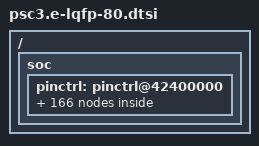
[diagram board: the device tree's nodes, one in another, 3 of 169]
/*
 * copyright (c) (2016-2025), Cypress Semiconductor Corporation
 * (an Infineon company) or an affiliate of Cypress Semiconductor Corporation.
 *
 * SPDX-License-Identifier: Apache-2.0
 *
 */

#include <zephyr/dt-bindings/gpio/gpio.h>
#include <zephyr/dt-bindings/pinctrl/ifx_cat1-pinctrl.h>
#include "psc3.dtsi"

/ {
	soc {

		pinctrl: pinctrl@42400000 {
			/* scb_i2c_scl */
			/omit-if-no-ref/ p1_3_scb1_i2c_scl: p1_3_scb1_i2c_scl {
				pinmux = <DT_CAT1_PINMUX(1, 3, HSIOM_SEL_ACT_7)>;
			};
			/omit-if-no-ref/ p2_1_scb1_i2c_scl: p2_1_scb1_i2c_scl {
				pinmux = <DT_CAT1_PINMUX(2, 1, HSIOM_SEL_ACT_7)>;
			};
			/omit-if-no-ref/ p3_2_scb4_i2c_scl: p3_2_scb4_i2c_scl {
				pinmux = <DT_CAT1_PINMUX(3, 2, HSIOM_SEL_ACT_7)>;
			};
			/omit-if-no-ref/ p4_2_scb4_i2c_scl: p4_2_scb4_i2c_scl {
				pinmux = <DT_CAT1_PINMUX(4, 2, HSIOM_SEL_ACT_7)>;
			};
			/omit-if-no-ref/ p5_1_scb3_i2c_scl: p5_1_scb3_i2c_scl {
				pinmux = <DT_CAT1_PINMUX(5, 1, HSIOM_SEL_ACT_7)>;
			};
			/omit-if-no-ref/ p6_1_scb3_i2c_scl: p6_1_scb3_i2c_scl {
				pinmux = <DT_CAT1_PINMUX(6, 1, HSIOM_SEL_ACT_7)>;
			};
			/omit-if-no-ref/ p7_0_scb2_i2c_scl: p7_0_scb2_i2c_scl {
				pinmux = <DT_CAT1_PINMUX(7, 0, HSIOM_SEL_ACT_7)>;
			};
			/omit-if-no-ref/ p8_1_scb5_i2c_scl: p8_1_scb5_i2c_scl {
				pinmux = <DT_CAT1_PINMUX(8, 1, HSIOM_SEL_ACT_7)>;
			};
			/omit-if-no-ref/ p9_0_scb0_i2c_scl: p9_0_scb0_i2c_scl {
				pinmux = <DT_CAT1_PINMUX(9, 0, HSIOM_SEL_DS_3)>;
			};

			/* scb_i2c_sda */
			/omit-if-no-ref/ p1_2_scb1_i2c_sda: p1_2_scb1_i2c_sda {
				pinmux = <DT_CAT1_PINMUX(1, 2, HSIOM_SEL_ACT_7)>;
			};
			/omit-if-no-ref/ p2_2_scb1_i2c_sda: p2_2_scb1_i2c_sda {
				pinmux = <DT_CAT1_PINMUX(2, 2, HSIOM_SEL_ACT_7)>;
			};
			/omit-if-no-ref/ p3_1_scb4_i2c_sda: p3_1_scb4_i2c_sda {
				pinmux = <DT_CAT1_PINMUX(3, 1, HSIOM_SEL_ACT_7)>;
			};
			/omit-if-no-ref/ p4_1_scb4_i2c_sda: p4_1_scb4_i2c_sda {
				pinmux = <DT_CAT1_PINMUX(4, 1, HSIOM_SEL_ACT_7)>;
			};
			/omit-if-no-ref/ p5_0_scb3_i2c_sda: p5_0_scb3_i2c_sda {
				pinmux = <DT_CAT1_PINMUX(5, 0, HSIOM_SEL_ACT_7)>;
			};
			/omit-if-no-ref/ p6_0_scb3_i2c_sda: p6_0_scb3_i2c_sda {
				pinmux = <DT_CAT1_PINMUX(6, 0, HSIOM_SEL_ACT_7)>;
			};
			/omit-if-no-ref/ p7_1_scb2_i2c_sda: p7_1_scb2_i2c_sda {
				pinmux = <DT_CAT1_PINMUX(7, 1, HSIOM_SEL_ACT_7)>;
			};
			/omit-if-no-ref/ p8_3_scb5_i2c_sda: p8_3_scb5_i2c_sda {
				pinmux = <DT_CAT1_PINMUX(8, 3, HSIOM_SEL_ACT_7)>;
			};
			/omit-if-no-ref/ p9_2_scb0_i2c_sda: p9_2_scb0_i2c_sda {
				pinmux = <DT_CAT1_PINMUX(9, 2, HSIOM_SEL_DS_3)>;
			};

			/* scb_spi_m_clk */
			/omit-if-no-ref/ p1_1_scb1_spi_m_clk: p1_1_scb1_spi_m_clk {
				pinmux = <DT_CAT1_PINMUX(1, 1, HSIOM_SEL_ACT_6)>;
			};
			/omit-if-no-ref/ p2_1_scb1_spi_m_clk: p2_1_scb1_spi_m_clk {
				pinmux = <DT_CAT1_PINMUX(2, 1, HSIOM_SEL_ACT_6)>;
			};
			/omit-if-no-ref/ p3_2_scb4_spi_m_clk: p3_2_scb4_spi_m_clk {
				pinmux = <DT_CAT1_PINMUX(3, 2, HSIOM_SEL_ACT_6)>;
			};
			/omit-if-no-ref/ p4_2_scb4_spi_m_clk: p4_2_scb4_spi_m_clk {
				pinmux = <DT_CAT1_PINMUX(4, 2, HSIOM_SEL_ACT_6)>;
			};
			/omit-if-no-ref/ p5_2_scb3_spi_m_clk: p5_2_scb3_spi_m_clk {
				pinmux = <DT_CAT1_PINMUX(5, 2, HSIOM_SEL_ACT_6)>;
			};
			/omit-if-no-ref/ p6_2_scb3_spi_m_clk: p6_2_scb3_spi_m_clk {
				pinmux = <DT_CAT1_PINMUX(6, 2, HSIOM_SEL_ACT_6)>;
			};
			/omit-if-no-ref/ p7_0_scb2_spi_m_clk: p7_0_scb2_spi_m_clk {
				pinmux = <DT_CAT1_PINMUX(7, 0, HSIOM_SEL_ACT_5)>;
			};
			/omit-if-no-ref/ p8_3_scb5_spi_m_clk: p8_3_scb5_spi_m_clk {
				pinmux = <DT_CAT1_PINMUX(8, 3, HSIOM_SEL_ACT_5)>;
			};
			/omit-if-no-ref/ p9_0_scb0_spi_m_clk: p9_0_scb0_spi_m_clk {
				pinmux = <DT_CAT1_PINMUX(9, 0, HSIOM_SEL_DS_1)>;
			};

			/* scb_spi_m_miso */
			/omit-if-no-ref/ p1_3_scb1_spi_m_miso: p1_3_scb1_spi_m_miso {
				pinmux = <DT_CAT1_PINMUX(1, 3, HSIOM_SEL_ACT_6)>;
			};
			/omit-if-no-ref/ p2_3_scb1_spi_m_miso: p2_3_scb1_spi_m_miso {
				pinmux = <DT_CAT1_PINMUX(2, 3, HSIOM_SEL_ACT_6)>;
			};
			/omit-if-no-ref/ p3_1_scb4_spi_m_miso: p3_1_scb4_spi_m_miso {
				pinmux = <DT_CAT1_PINMUX(3, 1, HSIOM_SEL_ACT_6)>;
			};
			/omit-if-no-ref/ p4_1_scb4_spi_m_miso: p4_1_scb4_spi_m_miso {
				pinmux = <DT_CAT1_PINMUX(4, 1, HSIOM_SEL_ACT_6)>;
			};
			/omit-if-no-ref/ p5_1_scb3_spi_m_miso: p5_1_scb3_spi_m_miso {
				pinmux = <DT_CAT1_PINMUX(5, 1, HSIOM_SEL_ACT_6)>;
			};
			/omit-if-no-ref/ p6_1_scb3_spi_m_miso: p6_1_scb3_spi_m_miso {
				pinmux = <DT_CAT1_PINMUX(6, 1, HSIOM_SEL_ACT_6)>;
			};
			/omit-if-no-ref/ p7_2_scb2_spi_m_miso: p7_2_scb2_spi_m_miso {
				pinmux = <DT_CAT1_PINMUX(7, 2, HSIOM_SEL_ACT_5)>;
			};
			/omit-if-no-ref/ p8_2_scb5_spi_m_miso: p8_2_scb5_spi_m_miso {
				pinmux = <DT_CAT1_PINMUX(8, 2, HSIOM_SEL_ACT_5)>;
			};
			/omit-if-no-ref/ p9_3_scb0_spi_m_miso: p9_3_scb0_spi_m_miso {
				pinmux = <DT_CAT1_PINMUX(9, 3, HSIOM_SEL_DS_1)>;
			};

			/* scb_spi_m_mosi */
			/omit-if-no-ref/ p1_2_scb1_spi_m_mosi: p1_2_scb1_spi_m_mosi {
				pinmux = <DT_CAT1_PINMUX(1, 2, HSIOM_SEL_ACT_6)>;
			};
			/omit-if-no-ref/ p2_2_scb1_spi_m_mosi: p2_2_scb1_spi_m_mosi {
				pinmux = <DT_CAT1_PINMUX(2, 2, HSIOM_SEL_ACT_6)>;
			};
			/omit-if-no-ref/ p3_0_scb4_spi_m_mosi: p3_0_scb4_spi_m_mosi {
				pinmux = <DT_CAT1_PINMUX(3, 0, HSIOM_SEL_ACT_6)>;
			};
			/omit-if-no-ref/ p4_0_scb4_spi_m_mosi: p4_0_scb4_spi_m_mosi {
				pinmux = <DT_CAT1_PINMUX(4, 0, HSIOM_SEL_ACT_6)>;
			};
			/omit-if-no-ref/ p5_0_scb3_spi_m_mosi: p5_0_scb3_spi_m_mosi {
				pinmux = <DT_CAT1_PINMUX(5, 0, HSIOM_SEL_ACT_6)>;
			};
			/omit-if-no-ref/ p6_0_scb3_spi_m_mosi: p6_0_scb3_spi_m_mosi {
				pinmux = <DT_CAT1_PINMUX(6, 0, HSIOM_SEL_ACT_6)>;
			};
			/omit-if-no-ref/ p7_1_scb2_spi_m_mosi: p7_1_scb2_spi_m_mosi {
				pinmux = <DT_CAT1_PINMUX(7, 1, HSIOM_SEL_ACT_5)>;
			};
			/omit-if-no-ref/ p8_1_scb5_spi_m_mosi: p8_1_scb5_spi_m_mosi {
				pinmux = <DT_CAT1_PINMUX(8, 1, HSIOM_SEL_ACT_5)>;
			};
			/omit-if-no-ref/ p9_2_scb0_spi_m_mosi: p9_2_scb0_spi_m_mosi {
				pinmux = <DT_CAT1_PINMUX(9, 2, HSIOM_SEL_DS_1)>;
			};

			/* scb_spi_m_select0 */
			/omit-if-no-ref/ p1_0_scb1_spi_m_select0: p1_0_scb1_spi_m_select0 {
				pinmux = <DT_CAT1_PINMUX(1, 0, HSIOM_SEL_ACT_6)>;
			};
			/omit-if-no-ref/ p2_0_scb1_spi_m_select0: p2_0_scb1_spi_m_select0 {
				pinmux = <DT_CAT1_PINMUX(2, 0, HSIOM_SEL_ACT_6)>;
			};
			/omit-if-no-ref/ p3_3_scb4_spi_m_select0: p3_3_scb4_spi_m_select0 {
				pinmux = <DT_CAT1_PINMUX(3, 3, HSIOM_SEL_ACT_6)>;
			};
			/omit-if-no-ref/ p4_3_scb4_spi_m_select0: p4_3_scb4_spi_m_select0 {
				pinmux = <DT_CAT1_PINMUX(4, 3, HSIOM_SEL_ACT_6)>;
			};
			/omit-if-no-ref/ p5_3_scb3_spi_m_select0: p5_3_scb3_spi_m_select0 {
				pinmux = <DT_CAT1_PINMUX(5, 3, HSIOM_SEL_ACT_6)>;
			};
			/omit-if-no-ref/ p6_3_scb3_spi_m_select0: p6_3_scb3_spi_m_select0 {
				pinmux = <DT_CAT1_PINMUX(6, 3, HSIOM_SEL_ACT_6)>;
			};
			/omit-if-no-ref/ p7_3_scb2_spi_m_select0: p7_3_scb2_spi_m_select0 {
				pinmux = <DT_CAT1_PINMUX(7, 3, HSIOM_SEL_ACT_5)>;
			};
			/omit-if-no-ref/ p8_0_scb5_spi_m_select0: p8_0_scb5_spi_m_select0 {
				pinmux = <DT_CAT1_PINMUX(8, 0, HSIOM_SEL_ACT_5)>;
			};
			/omit-if-no-ref/ p9_1_scb0_spi_m_select0: p9_1_scb0_spi_m_select0 {
				pinmux = <DT_CAT1_PINMUX(9, 1, HSIOM_SEL_DS_1)>;
			};

			/* scb_spi_m_select1 */
			/omit-if-no-ref/ p7_4_scb2_spi_m_select1: p7_4_scb2_spi_m_select1 {
				pinmux = <DT_CAT1_PINMUX(7, 4, HSIOM_SEL_ACT_5)>;
			};
			/omit-if-no-ref/ p8_4_scb5_spi_m_select1: p8_4_scb5_spi_m_select1 {
				pinmux = <DT_CAT1_PINMUX(8, 4, HSIOM_SEL_ACT_5)>;
			};
			/omit-if-no-ref/ p9_4_scb0_spi_m_select1: p9_4_scb0_spi_m_select1 {
				pinmux = <DT_CAT1_PINMUX(9, 4, HSIOM_SEL_DS_1)>;
			};

			/* scb_spi_m_select2 */
			/omit-if-no-ref/ p7_5_scb2_spi_m_select2: p7_5_scb2_spi_m_select2 {
				pinmux = <DT_CAT1_PINMUX(7, 5, HSIOM_SEL_ACT_5)>;
			};
			/omit-if-no-ref/ p8_5_scb5_spi_m_select2: p8_5_scb5_spi_m_select2 {
				pinmux = <DT_CAT1_PINMUX(8, 5, HSIOM_SEL_ACT_5)>;
			};
			/omit-if-no-ref/ p9_5_scb0_spi_m_select2: p9_5_scb0_spi_m_select2 {
				pinmux = <DT_CAT1_PINMUX(9, 5, HSIOM_SEL_DS_1)>;
			};

			/* scb_spi_s_clk */
			/omit-if-no-ref/ p1_1_scb1_spi_s_clk: p1_1_scb1_spi_s_clk {
				pinmux = <DT_CAT1_PINMUX(1, 1, HSIOM_SEL_ACT_6)>;
			};
			/omit-if-no-ref/ p2_1_scb1_spi_s_clk: p2_1_scb1_spi_s_clk {
				pinmux = <DT_CAT1_PINMUX(2, 1, HSIOM_SEL_ACT_6)>;
			};
			/omit-if-no-ref/ p3_2_scb4_spi_s_clk: p3_2_scb4_spi_s_clk {
				pinmux = <DT_CAT1_PINMUX(3, 2, HSIOM_SEL_ACT_6)>;
			};
			/omit-if-no-ref/ p4_2_scb4_spi_s_clk: p4_2_scb4_spi_s_clk {
				pinmux = <DT_CAT1_PINMUX(4, 2, HSIOM_SEL_ACT_6)>;
			};
			/omit-if-no-ref/ p5_2_scb3_spi_s_clk: p5_2_scb3_spi_s_clk {
				pinmux = <DT_CAT1_PINMUX(5, 2, HSIOM_SEL_ACT_6)>;
			};
			/omit-if-no-ref/ p6_2_scb3_spi_s_clk: p6_2_scb3_spi_s_clk {
				pinmux = <DT_CAT1_PINMUX(6, 2, HSIOM_SEL_ACT_6)>;
			};
			/omit-if-no-ref/ p7_0_scb2_spi_s_clk: p7_0_scb2_spi_s_clk {
				pinmux = <DT_CAT1_PINMUX(7, 0, HSIOM_SEL_ACT_5)>;
			};
			/omit-if-no-ref/ p8_3_scb5_spi_s_clk: p8_3_scb5_spi_s_clk {
				pinmux = <DT_CAT1_PINMUX(8, 3, HSIOM_SEL_ACT_5)>;
			};
			/omit-if-no-ref/ p9_0_scb0_spi_s_clk: p9_0_scb0_spi_s_clk {
				pinmux = <DT_CAT1_PINMUX(9, 0, HSIOM_SEL_DS_1)>;
			};

			/* scb_spi_s_miso */
			/omit-if-no-ref/ p1_3_scb1_spi_s_miso: p1_3_scb1_spi_s_miso {
				pinmux = <DT_CAT1_PINMUX(1, 3, HSIOM_SEL_ACT_6)>;
			};
			/omit-if-no-ref/ p2_3_scb1_spi_s_miso: p2_3_scb1_spi_s_miso {
				pinmux = <DT_CAT1_PINMUX(2, 3, HSIOM_SEL_ACT_6)>;
			};
			/omit-if-no-ref/ p3_1_scb4_spi_s_miso: p3_1_scb4_spi_s_miso {
				pinmux = <DT_CAT1_PINMUX(3, 1, HSIOM_SEL_ACT_6)>;
			};
			/omit-if-no-ref/ p4_1_scb4_spi_s_miso: p4_1_scb4_spi_s_miso {
				pinmux = <DT_CAT1_PINMUX(4, 1, HSIOM_SEL_ACT_6)>;
			};
			/omit-if-no-ref/ p5_1_scb3_spi_s_miso: p5_1_scb3_spi_s_miso {
				pinmux = <DT_CAT1_PINMUX(5, 1, HSIOM_SEL_ACT_6)>;
			};
			/omit-if-no-ref/ p6_1_scb3_spi_s_miso: p6_1_scb3_spi_s_miso {
				pinmux = <DT_CAT1_PINMUX(6, 1, HSIOM_SEL_ACT_6)>;
			};
			/omit-if-no-ref/ p7_2_scb2_spi_s_miso: p7_2_scb2_spi_s_miso {
				pinmux = <DT_CAT1_PINMUX(7, 2, HSIOM_SEL_ACT_5)>;
			};
			/omit-if-no-ref/ p8_2_scb5_spi_s_miso: p8_2_scb5_spi_s_miso {
				pinmux = <DT_CAT1_PINMUX(8, 2, HSIOM_SEL_ACT_5)>;
			};
			/omit-if-no-ref/ p9_3_scb0_spi_s_miso: p9_3_scb0_spi_s_miso {
				pinmux = <DT_CAT1_PINMUX(9, 3, HSIOM_SEL_DS_1)>;
			};

			/* scb_spi_s_mosi */
			/omit-if-no-ref/ p1_2_scb1_spi_s_mosi: p1_2_scb1_spi_s_mosi {
				pinmux = <DT_CAT1_PINMUX(1, 2, HSIOM_SEL_ACT_6)>;
			};
			/omit-if-no-ref/ p2_2_scb1_spi_s_mosi: p2_2_scb1_spi_s_mosi {
				pinmux = <DT_CAT1_PINMUX(2, 2, HSIOM_SEL_ACT_6)>;
			};
			/omit-if-no-ref/ p3_0_scb4_spi_s_mosi: p3_0_scb4_spi_s_mosi {
				pinmux = <DT_CAT1_PINMUX(3, 0, HSIOM_SEL_ACT_6)>;
			};
			/omit-if-no-ref/ p4_0_scb4_spi_s_mosi: p4_0_scb4_spi_s_mosi {
				pinmux = <DT_CAT1_PINMUX(4, 0, HSIOM_SEL_ACT_6)>;
			};
			/omit-if-no-ref/ p5_0_scb3_spi_s_mosi: p5_0_scb3_spi_s_mosi {
				pinmux = <DT_CAT1_PINMUX(5, 0, HSIOM_SEL_ACT_6)>;
			};
			/omit-if-no-ref/ p6_0_scb3_spi_s_mosi: p6_0_scb3_spi_s_mosi {
				pinmux = <DT_CAT1_PINMUX(6, 0, HSIOM_SEL_ACT_6)>;
			};
			/omit-if-no-ref/ p7_1_scb2_spi_s_mosi: p7_1_scb2_spi_s_mosi {
				pinmux = <DT_CAT1_PINMUX(7, 1, HSIOM_SEL_ACT_5)>;
			};
			/omit-if-no-ref/ p8_1_scb5_spi_s_mosi: p8_1_scb5_spi_s_mosi {
				pinmux = <DT_CAT1_PINMUX(8, 1, HSIOM_SEL_ACT_5)>;
			};
			/omit-if-no-ref/ p9_2_scb0_spi_s_mosi: p9_2_scb0_spi_s_mosi {
				pinmux = <DT_CAT1_PINMUX(9, 2, HSIOM_SEL_DS_1)>;
			};

			/* scb_spi_s_select0 */
			/omit-if-no-ref/ p1_0_scb1_spi_s_select0: p1_0_scb1_spi_s_select0 {
				pinmux = <DT_CAT1_PINMUX(1, 0, HSIOM_SEL_ACT_6)>;
			};
			/omit-if-no-ref/ p2_0_scb1_spi_s_select0: p2_0_scb1_spi_s_select0 {
				pinmux = <DT_CAT1_PINMUX(2, 0, HSIOM_SEL_ACT_6)>;
			};
			/omit-if-no-ref/ p3_3_scb4_spi_s_select0: p3_3_scb4_spi_s_select0 {
				pinmux = <DT_CAT1_PINMUX(3, 3, HSIOM_SEL_ACT_6)>;
			};
			/omit-if-no-ref/ p4_3_scb4_spi_s_select0: p4_3_scb4_spi_s_select0 {
				pinmux = <DT_CAT1_PINMUX(4, 3, HSIOM_SEL_ACT_6)>;
			};
			/omit-if-no-ref/ p5_3_scb3_spi_s_select0: p5_3_scb3_spi_s_select0 {
				pinmux = <DT_CAT1_PINMUX(5, 3, HSIOM_SEL_ACT_6)>;
			};
			/omit-if-no-ref/ p6_3_scb3_spi_s_select0: p6_3_scb3_spi_s_select0 {
				pinmux = <DT_CAT1_PINMUX(6, 3, HSIOM_SEL_ACT_6)>;
			};
			/omit-if-no-ref/ p7_3_scb2_spi_s_select0: p7_3_scb2_spi_s_select0 {
				pinmux = <DT_CAT1_PINMUX(7, 3, HSIOM_SEL_ACT_5)>;
			};
			/omit-if-no-ref/ p8_0_scb5_spi_s_select0: p8_0_scb5_spi_s_select0 {
				pinmux = <DT_CAT1_PINMUX(8, 0, HSIOM_SEL_ACT_5)>;
			};
			/omit-if-no-ref/ p9_1_scb0_spi_s_select0: p9_1_scb0_spi_s_select0 {
				pinmux = <DT_CAT1_PINMUX(9, 1, HSIOM_SEL_DS_1)>;
			};

			/* scb_spi_s_select1 */
			/omit-if-no-ref/ p7_4_scb2_spi_s_select1: p7_4_scb2_spi_s_select1 {
				pinmux = <DT_CAT1_PINMUX(7, 4, HSIOM_SEL_ACT_5)>;
			};
			/omit-if-no-ref/ p8_4_scb5_spi_s_select1: p8_4_scb5_spi_s_select1 {
				pinmux = <DT_CAT1_PINMUX(8, 4, HSIOM_SEL_ACT_5)>;
			};
			/omit-if-no-ref/ p9_4_scb0_spi_s_select1: p9_4_scb0_spi_s_select1 {
				pinmux = <DT_CAT1_PINMUX(9, 4, HSIOM_SEL_DS_1)>;
			};

			/* scb_spi_s_select2 */
			/omit-if-no-ref/ p7_5_scb2_spi_s_select2: p7_5_scb2_spi_s_select2 {
				pinmux = <DT_CAT1_PINMUX(7, 5, HSIOM_SEL_ACT_5)>;
			};
			/omit-if-no-ref/ p8_5_scb5_spi_s_select2: p8_5_scb5_spi_s_select2 {
				pinmux = <DT_CAT1_PINMUX(8, 5, HSIOM_SEL_ACT_5)>;
			};
			/omit-if-no-ref/ p9_5_scb0_spi_s_select2: p9_5_scb0_spi_s_select2 {
				pinmux = <DT_CAT1_PINMUX(9, 5, HSIOM_SEL_DS_1)>;
			};

			/* scb_uart_cts */
			/omit-if-no-ref/ p1_0_scb1_uart_cts: p1_0_scb1_uart_cts {
				pinmux = <DT_CAT1_PINMUX(1, 0, HSIOM_SEL_ACT_4)>;
			};
			/omit-if-no-ref/ p2_0_scb1_uart_cts: p2_0_scb1_uart_cts {
				pinmux = <DT_CAT1_PINMUX(2, 0, HSIOM_SEL_ACT_4)>;
			};
			/omit-if-no-ref/ p3_0_scb4_uart_cts: p3_0_scb4_uart_cts {
				pinmux = <DT_CAT1_PINMUX(3, 0, HSIOM_SEL_ACT_4)>;
			};
			/omit-if-no-ref/ p4_0_scb4_uart_cts: p4_0_scb4_uart_cts {
				pinmux = <DT_CAT1_PINMUX(4, 0, HSIOM_SEL_ACT_4)>;
			};
			/omit-if-no-ref/ p5_0_scb3_uart_cts: p5_0_scb3_uart_cts {
				pinmux = <DT_CAT1_PINMUX(5, 0, HSIOM_SEL_ACT_4)>;
			};
			/omit-if-no-ref/ p6_0_scb3_uart_cts: p6_0_scb3_uart_cts {
				pinmux = <DT_CAT1_PINMUX(6, 0, HSIOM_SEL_ACT_4)>;
			};
			/omit-if-no-ref/ p7_0_scb2_uart_cts: p7_0_scb2_uart_cts {
				pinmux = <DT_CAT1_PINMUX(7, 0, HSIOM_SEL_ACT_4)>;
			};
			/omit-if-no-ref/ p8_0_scb5_uart_cts: p8_0_scb5_uart_cts {
				pinmux = <DT_CAT1_PINMUX(8, 0, HSIOM_SEL_ACT_4)>;
			};
			/omit-if-no-ref/ p9_0_scb0_uart_cts: p9_0_scb0_uart_cts {
				pinmux = <DT_CAT1_PINMUX(9, 0, HSIOM_SEL_DS_2)>;
			};

			/* scb_uart_rts */
			/omit-if-no-ref/ p1_1_scb1_uart_rts: p1_1_scb1_uart_rts {
				pinmux = <DT_CAT1_PINMUX(1, 1, HSIOM_SEL_ACT_4)>;
			};
			/omit-if-no-ref/ p2_1_scb1_uart_rts: p2_1_scb1_uart_rts {
				pinmux = <DT_CAT1_PINMUX(2, 1, HSIOM_SEL_ACT_4)>;
			};
			/omit-if-no-ref/ p3_1_scb4_uart_rts: p3_1_scb4_uart_rts {
				pinmux = <DT_CAT1_PINMUX(3, 1, HSIOM_SEL_ACT_4)>;
			};
			/omit-if-no-ref/ p4_1_scb4_uart_rts: p4_1_scb4_uart_rts {
				pinmux = <DT_CAT1_PINMUX(4, 1, HSIOM_SEL_ACT_4)>;
			};
			/omit-if-no-ref/ p5_1_scb3_uart_rts: p5_1_scb3_uart_rts {
				pinmux = <DT_CAT1_PINMUX(5, 1, HSIOM_SEL_ACT_4)>;
			};
			/omit-if-no-ref/ p6_1_scb3_uart_rts: p6_1_scb3_uart_rts {
				pinmux = <DT_CAT1_PINMUX(6, 1, HSIOM_SEL_ACT_4)>;
			};
			/omit-if-no-ref/ p7_3_scb2_uart_rts: p7_3_scb2_uart_rts {
				pinmux = <DT_CAT1_PINMUX(7, 3, HSIOM_SEL_ACT_4)>;
			};
			/omit-if-no-ref/ p8_2_scb5_uart_rts: p8_2_scb5_uart_rts {
				pinmux = <DT_CAT1_PINMUX(8, 2, HSIOM_SEL_ACT_4)>;
			};
			/omit-if-no-ref/ p9_1_scb0_uart_rts: p9_1_scb0_uart_rts {
				pinmux = <DT_CAT1_PINMUX(9, 1, HSIOM_SEL_DS_2)>;
			};

			/* scb_uart_rx */
			/omit-if-no-ref/ p1_2_scb1_uart_rx: p1_2_scb1_uart_rx {
				pinmux = <DT_CAT1_PINMUX(1, 2, HSIOM_SEL_ACT_4)>;
			};
			/omit-if-no-ref/ p2_2_scb1_uart_rx: p2_2_scb1_uart_rx {
				pinmux = <DT_CAT1_PINMUX(2, 2, HSIOM_SEL_ACT_4)>;
			};
			/omit-if-no-ref/ p3_2_scb4_uart_rx: p3_2_scb4_uart_rx {
				pinmux = <DT_CAT1_PINMUX(3, 2, HSIOM_SEL_ACT_4)>;
			};
			/omit-if-no-ref/ p4_2_scb4_uart_rx: p4_2_scb4_uart_rx {
				pinmux = <DT_CAT1_PINMUX(4, 2, HSIOM_SEL_ACT_4)>;
			};
			/omit-if-no-ref/ p5_2_scb3_uart_rx: p5_2_scb3_uart_rx {
				pinmux = <DT_CAT1_PINMUX(5, 2, HSIOM_SEL_ACT_4)>;
			};
			/omit-if-no-ref/ p6_2_scb3_uart_rx: p6_2_scb3_uart_rx {
				pinmux = <DT_CAT1_PINMUX(6, 2, HSIOM_SEL_ACT_4)>;
			};
			/omit-if-no-ref/ p7_2_scb2_uart_rx: p7_2_scb2_uart_rx {
				pinmux = <DT_CAT1_PINMUX(7, 2, HSIOM_SEL_ACT_4)>;
			};
			/omit-if-no-ref/ p8_1_scb5_uart_rx: p8_1_scb5_uart_rx {
				pinmux = <DT_CAT1_PINMUX(8, 1, HSIOM_SEL_ACT_4)>;
			};
			/omit-if-no-ref/ p9_2_scb0_uart_rx: p9_2_scb0_uart_rx {
				pinmux = <DT_CAT1_PINMUX(9, 2, HSIOM_SEL_DS_2)>;
			};

			/* scb_uart_tx */
			/omit-if-no-ref/ p1_3_scb1_uart_tx: p1_3_scb1_uart_tx {
				pinmux = <DT_CAT1_PINMUX(1, 3, HSIOM_SEL_ACT_4)>;
			};
			/omit-if-no-ref/ p2_3_scb1_uart_tx: p2_3_scb1_uart_tx {
				pinmux = <DT_CAT1_PINMUX(2, 3, HSIOM_SEL_ACT_4)>;
			};
			/omit-if-no-ref/ p3_3_scb4_uart_tx: p3_3_scb4_uart_tx {
				pinmux = <DT_CAT1_PINMUX(3, 3, HSIOM_SEL_ACT_4)>;
			};
			/omit-if-no-ref/ p4_3_scb4_uart_tx: p4_3_scb4_uart_tx {
				pinmux = <DT_CAT1_PINMUX(4, 3, HSIOM_SEL_ACT_4)>;
			};
			/omit-if-no-ref/ p5_3_scb3_uart_tx: p5_3_scb3_uart_tx {
				pinmux = <DT_CAT1_PINMUX(5, 3, HSIOM_SEL_ACT_4)>;
			};
			/omit-if-no-ref/ p6_3_scb3_uart_tx: p6_3_scb3_uart_tx {
				pinmux = <DT_CAT1_PINMUX(6, 3, HSIOM_SEL_ACT_4)>;
			};
			/omit-if-no-ref/ p7_1_scb2_uart_tx: p7_1_scb2_uart_tx {
				pinmux = <DT_CAT1_PINMUX(7, 1, HSIOM_SEL_ACT_4)>;
			};
			/omit-if-no-ref/ p8_3_scb5_uart_tx: p8_3_scb5_uart_tx {
				pinmux = <DT_CAT1_PINMUX(8, 3, HSIOM_SEL_ACT_4)>;
			};
			/omit-if-no-ref/ p9_3_scb0_uart_tx: p9_3_scb0_uart_tx {
				pinmux = <DT_CAT1_PINMUX(9, 3, HSIOM_SEL_DS_2)>;
			};

			/* PWM tcpwm_line*/
			/omit-if-no-ref/ p4_0_pwm1_4: p4_0_pwm1_4 {
				pinmux = <DT_CAT1_PINMUX(4, 0, HSIOM_SEL_ACT_1)>;
			};
			/omit-if-no-ref/ p4_2_pwm1_5: p4_2_pwm1_5 {
				pinmux = <DT_CAT1_PINMUX(4, 2, HSIOM_SEL_ACT_1)>;
			};
			/omit-if-no-ref/ p4_4_pwm1_6: p4_4_pwm1_6 {
				pinmux = <DT_CAT1_PINMUX(4, 4, HSIOM_SEL_ACT_1)>;
			};
			/omit-if-no-ref/ p4_6_pwm1_7: p4_6_pwm1_7 {
				pinmux = <DT_CAT1_PINMUX(4, 6, HSIOM_SEL_ACT_1)>;
			};
			/omit-if-no-ref/ p6_0_pwm1_4: p6_0_pwm1_4 {
				pinmux = <DT_CAT1_PINMUX(6, 0, HSIOM_SEL_ACT_1)>;
			};
			/omit-if-no-ref/ p6_2_pwm1_5: p6_2_pwm1_5 {
				pinmux = <DT_CAT1_PINMUX(6, 2, HSIOM_SEL_ACT_1)>;
			};
			/omit-if-no-ref/ p7_0_pwm1_6: p7_0_pwm1_6 {
				pinmux = <DT_CAT1_PINMUX(7, 0, HSIOM_SEL_ACT_1)>;
			};
			/omit-if-no-ref/ p7_2_pwm1_7: p7_2_pwm1_7 {
				pinmux = <DT_CAT1_PINMUX(7, 2, HSIOM_SEL_ACT_1)>;
			};
			/omit-if-no-ref/ p2_0_pwm2_6: p2_0_pwm2_6 {
				pinmux = <DT_CAT1_PINMUX(2, 0, HSIOM_SEL_ACT_2)>;
			};
			/omit-if-no-ref/ p2_2_pwm2_7: p2_2_pwm2_7 {
				pinmux = <DT_CAT1_PINMUX(2, 2, HSIOM_SEL_ACT_2)>;
			};
			/omit-if-no-ref/ p8_0_pwm2_4: p8_0_pwm2_4 {
				pinmux = <DT_CAT1_PINMUX(8, 0, HSIOM_SEL_ACT_2)>;
			};
			/omit-if-no-ref/ p8_2_pwm2_5: p8_2_pwm2_5 {
				pinmux = <DT_CAT1_PINMUX(8, 2, HSIOM_SEL_ACT_2)>;
			};
			/omit-if-no-ref/ p9_0_pwm2_6: p9_0_pwm2_6 {
				pinmux = <DT_CAT1_PINMUX(9, 0, HSIOM_SEL_ACT_2)>;
			};
			/omit-if-no-ref/ p9_2_pwm2_7: p9_2_pwm2_7 {
				pinmux = <DT_CAT1_PINMUX(9, 2, HSIOM_SEL_ACT_2)>;
			};

			/* PWM tcpwm_line_compl*/
			/omit-if-no-ref/ p4_1_pwm1_4: p4_1_pwm1_4_compl {
				pinmux = <DT_CAT1_PINMUX(4, 1, HSIOM_SEL_ACT_1)>;
			};
			/omit-if-no-ref/ p4_3_pwm1_5: p4_3_pwm1_5_compl {
				pinmux = <DT_CAT1_PINMUX(4, 3, HSIOM_SEL_ACT_1)>;
			};
			/omit-if-no-ref/ p4_5_pwm1_6: p4_5_pwm1_6_compl {
				pinmux = <DT_CAT1_PINMUX(4, 5, HSIOM_SEL_ACT_1)>;
			};
			/omit-if-no-ref/ p4_7_pwm1_7: p4_7_pwm1_7_compl {
				pinmux = <DT_CAT1_PINMUX(4, 7, HSIOM_SEL_ACT_1)>;
			};
			/omit-if-no-ref/ p6_1_pwm1_4: p6_1_pwm1_4_compl {
				pinmux = <DT_CAT1_PINMUX(6, 1, HSIOM_SEL_ACT_1)>;
			};
			/omit-if-no-ref/ p6_3_pwm1_5: p6_3_pwm1_5_compl {
				pinmux = <DT_CAT1_PINMUX(6, 3, HSIOM_SEL_ACT_1)>;
			};
			/omit-if-no-ref/ p7_1_pwm1_6: p7_1_pwm1_6_compl {
				pinmux = <DT_CAT1_PINMUX(7, 1, HSIOM_SEL_ACT_1)>;
			};
			/omit-if-no-ref/ p7_3_pwm1_7: p7_3_pwm1_7_compl {
				pinmux = <DT_CAT1_PINMUX(7, 3, HSIOM_SEL_ACT_1)>;
			};
			/omit-if-no-ref/ p2_1_pwm2_6: p2_1_pwm2_6_compl {
				pinmux = <DT_CAT1_PINMUX(2, 1, HSIOM_SEL_ACT_2)>;
			};
			/omit-if-no-ref/ p2_3_pwm2_7: p2_3_pwm2_7_compl {
				pinmux = <DT_CAT1_PINMUX(2, 3, HSIOM_SEL_ACT_2)>;
			};
			/omit-if-no-ref/ p8_1_pwm2_4: p8_1_pwm2_4_compl {
				pinmux = <DT_CAT1_PINMUX(8, 1, HSIOM_SEL_ACT_2)>;
			};
			/omit-if-no-ref/ p8_3_pwm2_5: p8_3_pwm2_5_compl {
				pinmux = <DT_CAT1_PINMUX(8, 3, HSIOM_SEL_ACT_2)>;
			};
			/omit-if-no-ref/ p9_1_pwm2_6: p9_1_pwm2_6_compl {
				pinmux = <DT_CAT1_PINMUX(9, 1, HSIOM_SEL_ACT_2)>;
			};
			/omit-if-no-ref/ p9_3_pwm2_7: p9_3_pwm2_7_compl {
				pinmux = <DT_CAT1_PINMUX(9, 3, HSIOM_SEL_ACT_2)>;
			};

		};
	};
};
